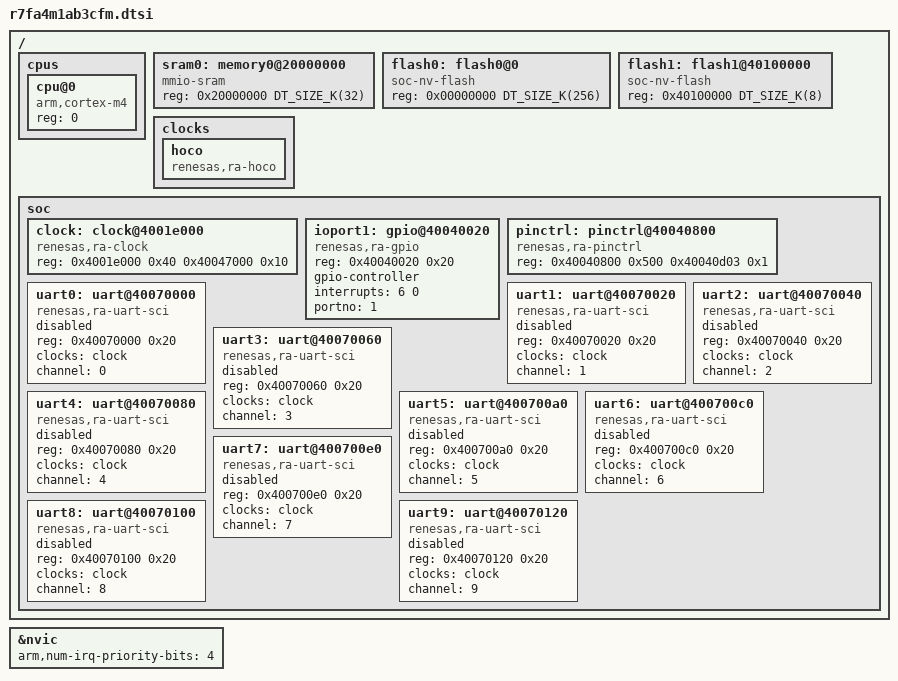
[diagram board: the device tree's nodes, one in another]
/*
 * Copyright (c) 2023 TOKITA Hiroshi <tokita.hiroshi@fujitsu.com>
 *
 * SPDX-License-Identifier: Apache-2.0
 */

#include <mem.h>
#include <freq.h>
#include <arm/armv7-m.dtsi>
#include <zephyr/dt-bindings/gpio/gpio.h>
#include <zephyr/dt-bindings/i2c/i2c.h>
#include <zephyr/dt-bindings/pwm/pwm.h>
#include <zephyr/dt-bindings/display/panel.h>

/ {
	cpus {
		#address-cells = <1>;
		#size-cells = <0>;

		cpu@0 {
			device_type = "cpu";
			compatible = "arm,cortex-m4";
			reg = <0>;
		};
	};

	sram0: memory0@20000000 {
		compatible = "mmio-sram";
		reg = <0x20000000 DT_SIZE_K(32)>;
	};

	flash0: flash0@0 {
		compatible = "soc-nv-flash";
		reg = <0x00000000 DT_SIZE_K(256)>;
	};

	flash1: flash1@40100000 {
		compatible = "soc-nv-flash";
		reg = <0x40100000 DT_SIZE_K(8)>;
	};

	clocks {
		hoco: hoco {
			compatible = "renesas,ra-hoco";
			#clock-cells = <0>;
		};
	};

	soc {
		clock: clock@4001e000 {
			compatible = "renesas,ra-clock";
			reg = <0x4001e000 0x40 0x40047000 0x10>;
                        reg-names = "system", "mstp";
			#clock-cells = <0>;
		};

		ioport1: gpio@40040020 {
			compatible = "renesas,ra-gpio";
			reg = <0x40040020 0x20>;
			gpio-controller;
			#gpio-cells = <2>;
			interrupts = <6 0>;
			portno = <1>;
		};

		pinctrl: pinctrl@40040800 {
			compatible = "renesas,ra-pinctrl";
			reg = <0x40040800 0x500 0x40040d03 0x1>;
                        reg-names = "pfs", "pmisc_pwpr";
			status = "okay";
		};

		uart0: uart@40070000 {
			compatible = "renesas,ra-uart-sci";
			reg = <0x40070000 0x20>;
			clocks = <&clock>;
			channel = <0>;
			status = "disabled";
		};

		uart1: uart@40070020 {
			compatible = "renesas,ra-uart-sci";
			reg = <0x40070020 0x20>;
			clocks = <&clock>;
			channel = <1>;
			status = "disabled";
		};

		uart2: uart@40070040 {
			compatible = "renesas,ra-uart-sci";
			reg = <0x40070040 0x20>;
			clocks = <&clock>;
			channel = <2>;
			status = "disabled";
		};

		uart3: uart@40070060 {
			compatible = "renesas,ra-uart-sci";
			reg = <0x40070060 0x20>;
			clocks = <&clock>;
			channel = <3>;
			status = "disabled";
		};

		uart4: uart@40070080 {
			compatible = "renesas,ra-uart-sci";
			reg = <0x40070080 0x20>;
			clocks = <&clock>;
			channel = <4>;
			status = "disabled";
		};

		uart5: uart@400700a0 {
			compatible = "renesas,ra-uart-sci";
			reg = <0x400700a0 0x20>;
			clocks = <&clock>;
			channel = <5>;
			status = "disabled";
		};

		uart6: uart@400700c0 {
			compatible = "renesas,ra-uart-sci";
			reg = <0x400700c0 0x20>;
			clocks = <&clock>;
			channel = <6>;
			status = "disabled";
		};

		uart7: uart@400700e0 {
			compatible = "renesas,ra-uart-sci";
			reg = <0x400700e0 0x20>;
			clocks = <&clock>;
			channel = <7>;
			status = "disabled";
		};

		uart8: uart@40070100 {
			compatible = "renesas,ra-uart-sci";
			reg = <0x40070100 0x20>;
			clocks = <&clock>;
			channel = <8>;
			status = "disabled";
		};

		uart9: uart@40070120 {
			compatible = "renesas,ra-uart-sci";
			reg = <0x40070120 0x20>;
			clocks = <&clock>;
			channel = <9>;
			status = "disabled";
		};
	};
};

&nvic {
	arm,num-irq-priority-bits = <4>;
};
